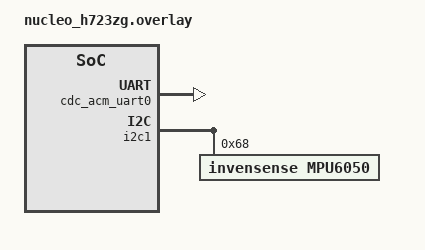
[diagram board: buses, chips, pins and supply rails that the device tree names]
&zephyr_udc0 {
    cdc_acm_uart0: cdc_acm_uart0 {
        compatible = "zephyr,cdc-acm-uart";
    };
};

&i2c1 {
    status = "okay";

    mpu6050: mpu6050@68 {
        compatible = "invensense,mpu6050";
        reg = <0x68>;
        label = "mpu6050";
    };
};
